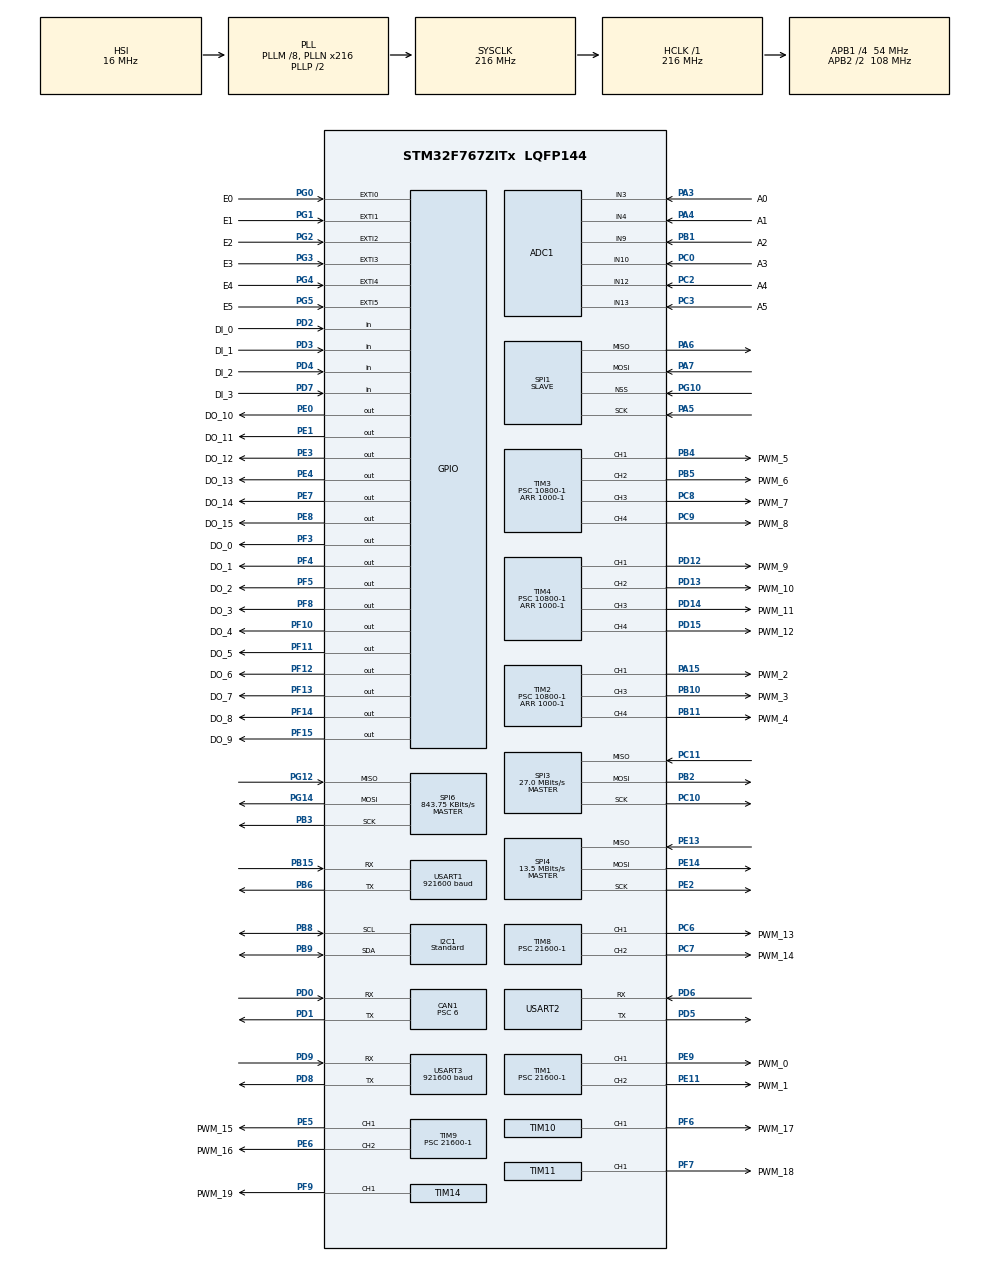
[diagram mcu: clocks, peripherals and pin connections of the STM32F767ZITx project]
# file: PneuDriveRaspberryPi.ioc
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ADC1.Channel-0\#ChannelRegularConversion=ADC_CHANNEL_3
ADC1.Channel-1\#ChannelRegularConversion=ADC_CHANNEL_4
ADC1.Channel-2\#ChannelRegularConversion=ADC_CHANNEL_9
ADC1.Channel-3\#ChannelRegularConversion=ADC_CHANNEL_10
ADC1.Channel-4\#ChannelRegularConversion=ADC_CHANNEL_12
ADC1.Channel-5\#ChannelRegularConversion=ADC_CHANNEL_13
ADC1.ContinuousConvMode=ENABLE
ADC1.DMAContinuousRequests=ENABLE
ADC1.EOCSelection=ADC_EOC_SEQ_CONV
ADC1.NbrOfConversion=6
ADC1.NbrOfConversionFlag=1
ADC1.Rank-0\#ChannelRegularConversion=1
ADC1.Rank-1\#ChannelRegularConversion=2
ADC1.Rank-2\#ChannelRegularConversion=3
ADC1.Rank-3\#ChannelRegularConversion=4
ADC1.Rank-4\#ChannelRegularConversion=5
ADC1.Rank-5\#ChannelRegularConversion=6
ADC1.SamplingTime-0\#ChannelRegularConversion=ADC_SAMPLETIME_480CYCLES
ADC1.SamplingTime-1\#ChannelRegularConversion=ADC_SAMPLETIME_480CYCLES
ADC1.SamplingTime-2\#ChannelRegularConversion=ADC_SAMPLETIME_480CYCLES
ADC1.SamplingTime-3\#ChannelRegularConversion=ADC_SAMPLETIME_480CYCLES
ADC1.SamplingTime-4\#ChannelRegularConversion=ADC_SAMPLETIME_480CYCLES
ADC1.SamplingTime-5\#ChannelRegularConversion=ADC_SAMPLETIME_480CYCLES
ADC1.ScanConvMode=ADC_SCAN_ENABLE
ADC1.master=1
CAN1.BS1=CAN_BS1_7TQ
CAN1.CalculateTimeQuantum=111.11111111111111
CAN1.NART=ENABLE
CAN1.Prescaler=6
CORTEX_M7.CPU_DCache=Enabled
CORTEX_M7.CPU_ICache=Enabled
Dma.ADC1.8.Direction=DMA_PERIPH_TO_MEMORY
Dma.ADC1.8.FIFOMode=DMA_FIFOMODE_DISABLE
Dma.ADC1.8.Instance=DMA2_Stream4
Dma.ADC1.8.MemDataAlignment=DMA_MDATAALIGN_HALFWORD
Dma.ADC1.8.MemInc=DMA_MINC_ENABLE
Dma.ADC1.8.Mode=DMA_CIRCULAR
Dma.ADC1.8.PeriphDataAlignment=DMA_PDATAALIGN_HALFWORD
Dma.ADC1.8.PeriphInc=DMA_PINC_DISABLE
Dma.ADC1.8.Priority=DMA_PRIORITY_LOW
Dma.Request0=SPI1_RX
Dma.Request1=SPI1_TX
Dma.Request10=USART1_TX
Dma.Request2=SPI3_RX
Dma.Request3=SPI3_TX
Dma.Request4=SPI4_RX
Dma.Request5=SPI4_TX
Dma.Request6=USART3_RX
Dma.Request7=USART3_TX
Dma.Request8=ADC1
Dma.Request9=USART1_RX
Dma.SPI1_RX.0.Direction=DMA_PERIPH_TO_MEMORY
Dma.SPI1_RX.0.FIFOMode=DMA_FIFOMODE_DISABLE
Dma.SPI1_RX.0.Instance=DMA2_Stream2
Dma.SPI1_RX.0.MemDataAlignment=DMA_MDATAALIGN_BYTE
Dma.SPI1_RX.0.MemInc=DMA_MINC_ENABLE
Dma.SPI1_RX.0.Mode=DMA_NORMAL
Dma.SPI1_RX.0.PeriphDataAlignment=DMA_PDATAALIGN_BYTE
Dma.SPI1_RX.0.PeriphInc=DMA_PINC_DISABLE
Dma.SPI1_RX.0.Priority=DMA_PRIORITY_VERY_HIGH
Dma.SPI1_TX.1.Direction=DMA_MEMORY_TO_PERIPH
Dma.SPI1_TX.1.FIFOMode=DMA_FIFOMODE_DISABLE
Dma.SPI1_TX.1.Instance=DMA2_Stream3
Dma.SPI1_TX.1.MemDataAlignment=DMA_MDATAALIGN_BYTE
Dma.SPI1_TX.1.MemInc=DMA_MINC_ENABLE
Dma.SPI1_TX.1.Mode=DMA_NORMAL
Dma.SPI1_TX.1.PeriphDataAlignment=DMA_PDATAALIGN_BYTE
Dma.SPI1_TX.1.PeriphInc=DMA_PINC_DISABLE
Dma.SPI1_TX.1.Priority=DMA_PRIORITY_VERY_HIGH
Dma.SPI3_RX.2.Direction=DMA_PERIPH_TO_MEMORY
Dma.SPI3_RX.2.FIFOMode=DMA_FIFOMODE_DISABLE
Dma.SPI3_RX.2.Instance=DMA1_Stream0
Dma.SPI3_RX.2.MemDataAlignment=DMA_MDATAALIGN_HALFWORD
Dma.SPI3_RX.2.MemInc=DMA_MINC_ENABLE
Dma.SPI3_RX.2.Mode=DMA_NORMAL
Dma.SPI3_RX.2.PeriphDataAlignment=DMA_PDATAALIGN_HALFWORD
Dma.SPI3_RX.2.PeriphInc=DMA_PINC_DISABLE
Dma.SPI3_RX.2.Priority=DMA_PRIORITY_HIGH
Dma.SPI3_TX.3.Direction=DMA_MEMORY_TO_PERIPH
Dma.SPI3_TX.3.FIFOMode=DMA_FIFOMODE_DISABLE
Dma.SPI3_TX.3.Instance=DMA1_Stream5
Dma.SPI3_TX.3.MemDataAlignment=DMA_MDATAALIGN_HALFWORD
Dma.SPI3_TX.3.MemInc=DMA_MINC_ENABLE
Dma.SPI3_TX.3.Mode=DMA_NORMAL
Dma.SPI3_TX.3.PeriphDataAlignment=DMA_PDATAALIGN_HALFWORD
Dma.SPI3_TX.3.PeriphInc=DMA_PINC_DISABLE
Dma.SPI3_TX.3.Priority=DMA_PRIORITY_HIGH
Dma.SPI4_RX.4.Direction=DMA_PERIPH_TO_MEMORY
Dma.SPI4_RX.4.FIFOMode=DMA_FIFOMODE_DISABLE
Dma.SPI4_RX.4.Instance=DMA2_Stream0
Dma.SPI4_RX.4.MemDataAlignment=DMA_MDATAALIGN_HALFWORD
Dma.SPI4_RX.4.MemInc=DMA_MINC_ENABLE
Dma.SPI4_RX.4.Mode=DMA_NORMAL
Dma.SPI4_RX.4.PeriphDataAlignment=DMA_PDATAALIGN_HALFWORD
Dma.SPI4_RX.4.PeriphInc=DMA_PINC_DISABLE
Dma.SPI4_RX.4.Priority=DMA_PRIORITY_MEDIUM
Dma.SPI4_TX.5.Direction=DMA_MEMORY_TO_PERIPH
Dma.SPI4_TX.5.FIFOMode=DMA_FIFOMODE_DISABLE
Dma.SPI4_TX.5.Instance=DMA2_Stream1
Dma.SPI4_TX.5.MemDataAlignment=DMA_MDATAALIGN_HALFWORD
Dma.SPI4_TX.5.MemInc=DMA_MINC_ENABLE
Dma.SPI4_TX.5.Mode=DMA_NORMAL
Dma.SPI4_TX.5.PeriphDataAlignment=DMA_PDATAALIGN_HALFWORD
Dma.SPI4_TX.5.PeriphInc=DMA_PINC_DISABLE
Dma.SPI4_TX.5.Priority=DMA_PRIORITY_MEDIUM
Dma.USART1_RX.9.Direction=DMA_PERIPH_TO_MEMORY
Dma.USART1_RX.9.FIFOMode=DMA_FIFOMODE_DISABLE
Dma.USART1_RX.9.Instance=DMA2_Stream5
Dma.USART1_RX.9.MemDataAlignment=DMA_MDATAALIGN_BYTE
Dma.USART1_RX.9.MemInc=DMA_MINC_ENABLE
Dma.USART1_RX.9.Mode=DMA_CIRCULAR
Dma.USART1_RX.9.PeriphDataAlignment=DMA_PDATAALIGN_BYTE
Dma.USART1_RX.9.PeriphInc=DMA_PINC_DISABLE
Dma.USART1_RX.9.Priority=DMA_PRIORITY_LOW
Dma.USART1_TX.10.Direction=DMA_MEMORY_TO_PERIPH
Dma.USART1_TX.10.FIFOMode=DMA_FIFOMODE_DISABLE
Dma.USART1_TX.10.Instance=DMA2_Stream7
Dma.USART1_TX.10.MemDataAlignment=DMA_MDATAALIGN_BYTE
Dma.USART1_TX.10.MemInc=DMA_MINC_ENABLE
Dma.USART1_TX.10.Mode=DMA_NORMAL
Dma.USART1_TX.10.PeriphDataAlignment=DMA_PDATAALIGN_BYTE
Dma.USART1_TX.10.PeriphInc=DMA_PINC_DISABLE
Dma.USART1_TX.10.Priority=DMA_PRIORITY_LOW
Dma.USART3_RX.6.Direction=DMA_PERIPH_TO_MEMORY
Dma.USART3_RX.6.FIFOMode=DMA_FIFOMODE_DISABLE
Dma.USART3_RX.6.Instance=DMA1_Stream1
Dma.USART3_RX.6.MemDataAlignment=DMA_MDATAALIGN_BYTE
Dma.USART3_RX.6.MemInc=DMA_MINC_ENABLE
Dma.USART3_RX.6.Mode=DMA_NORMAL
Dma.USART3_RX.6.PeriphDataAlignment=DMA_PDATAALIGN_BYTE
Dma.USART3_RX.6.PeriphInc=DMA_PINC_DISABLE
Dma.USART3_RX.6.Priority=DMA_PRIORITY_HIGH
Dma.USART3_TX.7.Direction=DMA_MEMORY_TO_PERIPH
Dma.USART3_TX.7.FIFOMode=DMA_FIFOMODE_DISABLE
Dma.USART3_TX.7.Instance=DMA1_Stream4
Dma.USART3_TX.7.MemDataAlignment=DMA_MDATAALIGN_BYTE
Dma.USART3_TX.7.MemInc=DMA_MINC_ENABLE
Dma.USART3_TX.7.Mode=DMA_NORMAL
Dma.USART3_TX.7.PeriphDataAlignment=DMA_PDATAALIGN_BYTE
Dma.USART3_TX.7.PeriphInc=DMA_PINC_DISABLE
Dma.USART3_TX.7.Priority=DMA_PRIORITY_MEDIUM
FREERTOS.INCLUDE_vTaskDelayUntil=1
FREERTOS.MEMORY_ALLOCATION=1
FREERTOS.Tasks01=sendTask,-1,4096,sendTaskFunc,Default,NULL,Static,sendTaskBuffer,sendTaskControlBlock;controlTask,1,4096,controlTaskFunc,Default,NULL,Static,controlTaskBuffer,controlTaskControlBlock
FREERTOS.configUSE_TRACE_FACILITY=0
I2C1.I2C_Speed_Mode=I2C_Standard
I2C1.Timing=0x20404768
Mcu.Family=STM32F7
Mcu.Name=STM32F767ZITx
Mcu.Package=LQFP144
NVIC.CAN1_RX0_IRQn=true\:5\:0\:false\:false\:true\:true\:true\:true
NVIC.CAN1_RX1_IRQn=true\:5\:0\:false\:false\:true\:true\:true\:true
NVIC.DMA1_Stream0_IRQn=true\:5\:0\:false\:false\:true\:true\:false\:true
NVIC.DMA1_Stream1_IRQn=true\:5\:0\:false\:false\:true\:true\:false\:true
NVIC.DMA1_Stream4_IRQn=true\:5\:0\:false\:false\:true\:true\:false\:true
NVIC.DMA1_Stream5_IRQn=true\:5\:0\:false\:false\:true\:true\:false\:true
NVIC.DMA2_Stream0_IRQn=true\:5\:0\:false\:false\:true\:true\:false\:true
NVIC.DMA2_Stream1_IRQn=true\:5\:0\:false\:false\:true\:true\:false\:true
NVIC.DMA2_Stream2_IRQn=true\:5\:0\:false\:false\:true\:true\:false\:true
NVIC.DMA2_Stream3_IRQn=true\:5\:0\:false\:false\:true\:true\:false\:true
NVIC.DMA2_Stream4_IRQn=true\:5\:0\:false\:false\:true\:true\:false\:true
NVIC.DMA2_Stream5_IRQn=true\:5\:0\:false\:false\:true\:true\:false\:true
NVIC.DMA2_Stream7_IRQn=true\:5\:0\:false\:false\:true\:true\:false\:true
NVIC.EXTI0_IRQn=true\:5\:0\:false\:false\:true\:true\:true\:true
NVIC.EXTI1_IRQn=true\:5\:0\:false\:false\:true\:true\:true\:true
NVIC.EXTI2_IRQn=true\:5\:0\:false\:false\:true\:true\:true\:true
NVIC.EXTI3_IRQn=true\:5\:0\:false\:false\:true\:true\:true\:true
NVIC.EXTI4_IRQn=true\:5\:0\:false\:false\:true\:true\:true\:true
NVIC.EXTI9_5_IRQn=true\:5\:0\:false\:false\:true\:true\:true\:true
NVIC.I2C1_EV_IRQn=true\:0\:0\:false\:false\:true\:false\:true\:true
NVIC.PriorityGroup=NVIC_PRIORITYGROUP_4
NVIC.SPI6_IRQn=true\:5\:0\:false\:false\:true\:true\:true\:true
NVIC.TIM1_UP_TIM10_IRQn=true\:5\:0\:false\:false\:true\:true\:true\:true
NVIC.TIM5_IRQn=true\:0\:0\:false\:false\:true\:false\:false\:true
NVIC.TimeBase=TIM5_IRQn
NVIC.TimeBaseIP=TIM5
NVIC.USART1_IRQn=true\:5\:0\:false\:false\:true\:true\:true\:true
NVIC.USART2_IRQn=true\:5\:0\:false\:false\:true\:true\:true\:true
NVIC.USART3_IRQn=true\:5\:0\:false\:false\:true\:true\:true\:true
PA13.Signal=SYS_JTMS-SWDIO
PA14.Signal=SYS_JTCK-SWCLK
PA15.GPIO_Label=PWM_2
PA15.Signal=S_TIM2_CH1_ETR
PA3.GPIO_Label=A0
PA3.Signal=ADCx_IN3
PA4.GPIO_Label=A1
PA4.Signal=ADCx_IN4
PA5.Mode=Full_Duplex_Slave
PA5.Signal=SPI1_SCK
PA6.Mode=Full_Duplex_Slave
PA6.Signal=SPI1_MISO
PA7.GPIO_PuPd=GPIO_PULLUP
PA7.Mode=Full_Duplex_Slave
PA7.Signal=SPI1_MOSI
PB1.GPIO_Label=A2
PB1.Signal=ADCx_IN9
PB10.GPIO_Label=PWM_3
PB10.Signal=S_TIM2_CH3
PB11.GPIO_Label=PWM_4
PB11.Signal=S_TIM2_CH4
PB15.GPIO_PuPd=GPIO_PULLDOWN
PB15.Mode=Asynchronous
PB15.Signal=USART1_RX
PB2.Mode=Full_Duplex_Master
PB2.Signal=SPI3_MOSI
PB3.Mode=Full_Duplex_Master
PB3.Signal=SPI6_SCK
PB4.GPIO_Label=PWM_5
PB4.Signal=S_TIM3_CH1
PB5.GPIO_Label=PWM_6
PB5.Signal=S_TIM3_CH2
PB6.GPIO_PuPd=GPIO_PULLDOWN
PB6.Mode=Asynchronous
PB6.Signal=USART1_TX
PB8.Mode=I2C
PB8.Signal=I2C1_SCL
PB9.Mode=I2C
PB9.Signal=I2C1_SDA
PC0.GPIO_Label=A3
PC0.Signal=ADCx_IN10
PC10.Mode=Full_Duplex_Master
PC10.Signal=SPI3_SCK
PC11.Mode=Full_Duplex_Master
PC11.Signal=SPI3_MISO
PC2.GPIO_Label=A4
PC2.Signal=ADCx_IN12
PC3.GPIO_Label=A5
PC3.Signal=ADCx_IN13
PC6.GPIO_Label=PWM_13
PC6.Signal=S_TIM8_CH1
PC7.GPIO_Label=PWM_14
PC7.Signal=S_TIM8_CH2
PC8.GPIO_Label=PWM_7
PC8.Signal=S_TIM3_CH3
PC9.GPIO_Label=PWM_8
PC9.Signal=S_TIM3_CH4
PD0.Mode=Master
PD0.Signal=CAN1_RX
PD1.Mode=Master
PD1.Signal=CAN1_TX
PD12.GPIO_Label=PWM_9
PD12.Signal=S_TIM4_CH1
PD13.GPIO_Label=PWM_10
PD13.Signal=S_TIM4_CH2
PD14.GPIO_Label=PWM_11
PD14.Signal=S_TIM4_CH3
PD15.GPIO_Label=PWM_12
PD15.Signal=S_TIM4_CH4
PD2.GPIO_Label=DI_0
PD2.Signal=GPIO_Input
PD3.GPIO_Label=DI_1
PD3.Signal=GPIO_Input
PD4.GPIO_Label=DI_2
PD4.Signal=GPIO_Input
PD5.GPIO_PuPd=GPIO_PULLDOWN
PD5.Mode=Asynchronous
PD5.Signal=USART2_TX
PD6.GPIO_PuPd=GPIO_PULLDOWN
PD6.Mode=Asynchronous
PD6.Signal=USART2_RX
PD7.GPIO_Label=DI_3
PD7.Signal=GPIO_Input
PD8.GPIO_PuPd=GPIO_PULLDOWN
PD8.Mode=Asynchronous
PD8.Signal=USART3_TX
PD9.GPIO_PuPd=GPIO_PULLDOWN
PD9.Mode=Asynchronous
PD9.Signal=USART3_RX
PE0.GPIO_Label=DO_10
PE0.GPIO_PuPd=GPIO_PULLDOWN
PE0.Signal=GPIO_Output
PE1.GPIO_Label=DO_11
PE1.GPIO_PuPd=GPIO_PULLDOWN
PE1.Signal=GPIO_Output
PE11.GPIO_Label=PWM_1
PE11.Signal=S_TIM1_CH2
PE13.Mode=Full_Duplex_Master
PE13.Signal=SPI4_MISO
PE14.Mode=Full_Duplex_Master
PE14.Signal=SPI4_MOSI
PE2.Mode=Full_Duplex_Master
PE2.Signal=SPI4_SCK
PE3.GPIO_Label=DO_12
PE3.GPIO_PuPd=GPIO_PULLDOWN
PE3.Signal=GPIO_Output
PE4.GPIO_Label=DO_13
PE4.GPIO_PuPd=GPIO_PULLDOWN
PE4.Signal=GPIO_Output
PE5.GPIO_Label=PWM_15
PE5.Signal=S_TIM9_CH1
PE6.GPIO_Label=PWM_16
PE6.Signal=S_TIM9_CH2
PE7.GPIO_Label=DO_14
PE7.GPIO_PuPd=GPIO_PULLDOWN
PE7.Signal=GPIO_Output
PE8.GPIO_Label=DO_15
PE8.GPIO_PuPd=GPIO_PULLDOWN
PE8.Signal=GPIO_Output
PE9.GPIO_Label=PWM_0
PE9.Signal=S_TIM1_CH1
PF10.GPIO_Label=DO_4
PF10.GPIO_PuPd=GPIO_PULLDOWN
PF10.Signal=GPIO_Output
PF11.GPIO_Label=DO_5
PF11.GPIO_PuPd=GPIO_PULLDOWN
PF11.Signal=GPIO_Output
PF12.GPIO_Label=DO_6
PF12.GPIO_PuPd=GPIO_PULLDOWN
PF12.Signal=GPIO_Output
PF13.GPIO_Label=DO_7
PF13.GPIO_PuPd=GPIO_PULLDOWN
PF13.Signal=GPIO_Output
PF14.GPIO_Label=DO_8
PF14.GPIO_PuPd=GPIO_PULLDOWN
PF14.Signal=GPIO_Output
PF15.GPIO_Label=DO_9
PF15.GPIO_PuPd=GPIO_PULLDOWN
PF15.Signal=GPIO_Output
PF3.GPIO_Label=DO_0
PF3.GPIO_PuPd=GPIO_PULLDOWN
PF3.Signal=GPIO_Output
PF4.GPIO_Label=DO_1
PF4.GPIO_PuPd=GPIO_PULLDOWN
PF4.Signal=GPIO_Output
PF5.GPIO_Label=DO_2
PF5.GPIO_PuPd=GPIO_PULLDOWN
PF5.Signal=GPIO_Output
PF6.GPIO_Label=PWM_17
PF6.Signal=S_TIM10_CH1
PF7.GPIO_Label=PWM_18
PF7.Signal=S_TIM11_CH1
PF8.GPIO_Label=DO_3
PF8.GPIO_PuPd=GPIO_PULLDOWN
PF8.Signal=GPIO_Output
PF9.GPIO_Label=PWM_19
PF9.Signal=S_TIM14_CH1
PG0.GPIO_Label=E0
PG0.GPIO_ModeDefaultEXTI=GPIO_MODE_IT_FALLING
PG0.GPIO_PuPd=GPIO_PULLDOWN
PG0.Signal=GPXTI0
PG1.GPIO_Label=E1
PG1.GPIO_ModeDefaultEXTI=GPIO_MODE_IT_FALLING
PG1.GPIO_PuPd=GPIO_PULLDOWN
PG1.Signal=GPXTI1
PG10.Mode=NSS_Signal_Hard_Input
PG10.Signal=SPI1_NSS
PG12.Mode=Full_Duplex_Master
PG12.Signal=SPI6_MISO
PG14.Mode=Full_Duplex_Master
PG14.Signal=SPI6_MOSI
PG2.GPIO_Label=E2
PG2.GPIO_ModeDefaultEXTI=GPIO_MODE_IT_FALLING
PG2.GPIO_PuPd=GPIO_PULLDOWN
PG2.Signal=GPXTI2
PG3.GPIO_Label=E3
PG3.GPIO_ModeDefaultEXTI=GPIO_MODE_IT_FALLING
PG3.GPIO_PuPd=GPIO_PULLDOWN
PG3.Signal=GPXTI3
PG4.GPIO_Label=E4
PG4.GPIO_ModeDefaultEXTI=GPIO_MODE_IT_FALLING
PG4.GPIO_PuPd=GPIO_PULLDOWN
PG4.Signal=GPXTI4
PG5.GPIO_Label=E5
PG5.GPIO_ModeDefaultEXTI=GPIO_MODE_IT_FALLING
PG5.GPIO_PuPd=GPIO_PULLDOWN
PG5.Signal=GPXTI5
ProjectManager.HeapSize=0x200
ProjectManager.StackSize=0x400
ProjectManager.TargetToolchain=STM32CubeIDE
RCC.AHBFreq_Value=216000000
RCC.APB1CLKDivider=RCC_HCLK_DIV4
RCC.APB1Freq_Value=54000000
RCC.APB1TimFreq_Value=108000000
RCC.APB2CLKDivider=RCC_HCLK_DIV2
RCC.APB2Freq_Value=108000000
RCC.APB2TimFreq_Value=216000000
RCC.CortexFreq_Value=216000000
RCC.HCLKFreq_Value=216000000
RCC.HSE_VALUE=25000000
RCC.HSI_VALUE=16000000
RCC.LSE_VALUE=32768
RCC.PLLM=8
RCC.PLLN=216
RCC.SYSCLKFreq_VALUE=216000000
RCC.SYSCLKSource=RCC_SYSCLKSOURCE_PLLCLK
RCC.USBFreq_Value=216000000
RCC.VCOOutputFreq_Value=432000000
SH.ADCx_IN10.0=ADC1_IN10,IN10
SH.ADCx_IN12.0=ADC1_IN12,IN12
SH.ADCx_IN13.0=ADC1_IN13,IN13
SH.ADCx_IN3.0=ADC1_IN3,IN3
SH.ADCx_IN4.0=ADC1_IN4,IN4
SH.ADCx_IN9.0=ADC1_IN9,IN9
SH.S_TIM10_CH1.0=TIM10_CH1,PWM Generation1 CH1
SH.S_TIM11_CH1.0=TIM11_CH1,PWM Generation1 CH1
SH.S_TIM14_CH1.0=TIM14_CH1,PWM Generation1 CH1
SH.S_TIM1_CH1.0=TIM1_CH1,PWM Generation1 CH1
SH.S_TIM1_CH2.0=TIM1_CH2,PWM Generation2 CH2
SH.S_TIM2_CH1_ETR.0=TIM2_CH1,PWM Generation1 CH1
SH.S_TIM2_CH3.0=TIM2_CH3,PWM Generation3 CH3
SH.S_TIM2_CH4.0=TIM2_CH4,PWM Generation4 CH4
SH.S_TIM3_CH1.0=TIM3_CH1,PWM Generation1 CH1
SH.S_TIM3_CH2.0=TIM3_CH2,PWM Generation2 CH2
SH.S_TIM3_CH3.0=TIM3_CH3,PWM Generation3 CH3
SH.S_TIM3_CH4.0=TIM3_CH4,PWM Generation4 CH4
SH.S_TIM4_CH1.0=TIM4_CH1,PWM Generation1 CH1
SH.S_TIM4_CH2.0=TIM4_CH2,PWM Generation2 CH2
SH.S_TIM4_CH3.0=TIM4_CH3,PWM Generation3 CH3
SH.S_TIM4_CH4.0=TIM4_CH4,PWM Generation4 CH4
SH.S_TIM8_CH1.0=TIM8_CH1,PWM Generation1 CH1
SH.S_TIM8_CH2.0=TIM8_CH2,PWM Generation2 CH2
SH.S_TIM9_CH1.0=TIM9_CH1,PWM Generation1 CH1
SH.S_TIM9_CH2.0=TIM9_CH2,PWM Generation2 CH2
SPI1.CLKPhase=SPI_PHASE_2EDGE
SPI1.CLKPolarity=SPI_POLARITY_LOW
SPI1.DataSize=SPI_DATASIZE_8BIT
SPI1.Direction=SPI_DIRECTION_2LINES
SPI1.Mode=SPI_MODE_SLAVE
SPI1.VirtualNSS=VM_NSSHARD
SPI1.VirtualType=VM_SLAVE
SPI3.BaudRatePrescaler=SPI_BAUDRATEPRESCALER_2
SPI3.CLKPhase=SPI_PHASE_1EDGE
SPI3.CLKPolarity=SPI_POLARITY_LOW
SPI3.CalculateBaudRate=27.0 MBits/s
SPI3.DataSize=SPI_DATASIZE_8BIT
SPI3.Direction=SPI_DIRECTION_2LINES
SPI3.Mode=SPI_MODE_MASTER
SPI3.VirtualType=VM_MASTER
SPI4.BaudRatePrescaler=SPI_BAUDRATEPRESCALER_8
SPI4.CLKPolarity=SPI_POLARITY_HIGH
SPI4.CalculateBaudRate=13.5 MBits/s
SPI4.DataSize=SPI_DATASIZE_16BIT
SPI4.Direction=SPI_DIRECTION_2LINES
SPI4.Mode=SPI_MODE_MASTER
SPI4.VirtualType=VM_MASTER
SPI6.BaudRatePrescaler=SPI_BAUDRATEPRESCALER_128
SPI6.CalculateBaudRate=843.75 KBits/s
SPI6.DataSize=SPI_DATASIZE_16BIT
SPI6.Direction=SPI_DIRECTION_2LINES
SPI6.Mode=SPI_MODE_MASTER
SPI6.VirtualType=VM_MASTER
TIM1.Channel-PWM\ Generation1\ CH1=TIM_CHANNEL_1
TIM1.Channel-PWM\ Generation2\ CH2=TIM_CHANNEL_2
TIM1.Period=1000-1
TIM1.Prescaler=21600-1
TIM10.Channel=TIM_CHANNEL_1
TIM10.Period=1000-1
TIM10.Prescaler=21600-1
TIM11.Channel=TIM_CHANNEL_1
TIM11.Period=1000-1
TIM11.Prescaler=21600-1
TIM14.Channel=TIM_CHANNEL_1
TIM14.Period=1000-1
TIM14.Prescaler=10800-1
TIM2.Channel-PWM\ Generation1\ CH1=TIM_CHANNEL_1
TIM2.Channel-PWM\ Generation3\ CH3=TIM_CHANNEL_3
TIM2.Channel-PWM\ Generation4\ CH4=TIM_CHANNEL_4
TIM2.Period=1000-1
TIM2.Prescaler=10800-1
TIM3.Channel-PWM\ Generation1\ CH1=TIM_CHANNEL_1
TIM3.Channel-PWM\ Generation2\ CH2=TIM_CHANNEL_2
TIM3.Channel-PWM\ Generation3\ CH3=TIM_CHANNEL_3
TIM3.Channel-PWM\ Generation4\ CH4=TIM_CHANNEL_4
TIM3.Period=1000-1
TIM3.Prescaler=10800-1
TIM4.Channel-PWM\ Generation1\ CH1=TIM_CHANNEL_1
TIM4.Channel-PWM\ Generation2\ CH2=TIM_CHANNEL_2
TIM4.Channel-PWM\ Generation3\ CH3=TIM_CHANNEL_3
TIM4.Channel-PWM\ Generation4\ CH4=TIM_CHANNEL_4
TIM4.Period=1000-1
TIM4.Prescaler=10800-1
TIM7.Period=65535
TIM8.Channel-PWM\ Generation1\ CH1=TIM_CHANNEL_1
TIM8.Channel-PWM\ Generation2\ CH2=TIM_CHANNEL_2
TIM8.Period=1000-1
TIM8.Prescaler=21600-1
TIM9.Channel-PWM\ Generation1\ CH1=TIM_CHANNEL_1
TIM9.Channel-PWM\ Generation2\ CH2=TIM_CHANNEL_2
TIM9.Period=1000-1
TIM9.Prescaler=21600-1
USART1.BaudRate=921600
USART1.VirtualMode-Asynchronous=VM_ASYNC
USART2.VirtualMode-Asynchronous=VM_ASYNC
USART3.BaudRate=921600
USART3.VirtualMode-Asynchronous=VM_ASYNC
VP_FREERTOS_VS_CMSIS_V1.Mode=CMSIS_V1
VP_SYS_VS_tim5.Mode=TIM5
VP_TIM10_VS_ClockSourceINT.Mode=Enable_Timer
VP_TIM11_VS_ClockSourceINT.Mode=Enable_Timer
VP_TIM14_VS_ClockSourceINT.Mode=Enable_Timer
VP_TIM1_VS_ClockSourceINT.Mode=Internal
VP_TIM2_VS_ClockSourceINT.Mode=Internal
VP_TIM7_VS_ClockSourceINT.Mode=Enable_Timer
VP_TIM8_VS_ClockSourceINT.Mode=Internal
VP_TIM9_VS_ClockSourceINT.Mode=Internal
board=custom

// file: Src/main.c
/* USER CODE BEGIN Header */
/**
  ******************************************************************************
  * @file           : main.c
  * @brief          : Main program body
  ******************************************************************************
  * @attention
  *
  * <h2><center>&copy; Copyright (c) 2019 STMicroelectronics.
  * All rights reserved.</center></h2>
  *
  * This software component is licensed by ST under BSD 3-Clause license,
  * the "License"; You may not use this file except in compliance with the
  * License. You may obtain a copy of the License at:
  *                        opensource.org/licenses/BSD-3-Clause
  *
  ******************************************************************************
  */
/* USER CODE END Header */
#include "main.h"
#include "cmsis_os.h"
#include "adc.h"
#include "can.h"
#include "dma.h"
#include "i2c.h"
#include "spi.h"
#include "tim.h"
#include "usart.h"
#include "gpio.h"

/* USER CODE BEGIN Includes */
#include "PneuDriveLL.h"
#include "myUsartFunction.h"
#include "ADBoard.h"
#include "DABoard.h"
#include "PWMBoardI2C.h"
#include "PWMBoardSPI.h"
#include "builtInAnalog.h"
#include "builtInPWM.h"
#include "builtInDigital.h"
#include "spiSlave.h"
/* USER CODE END Includes */

void SystemClock_Config(void);
void MX_FREERTOS_Init(void);

int main(void)
{

  /* Enable I-Cache---------------------------------------------------------*/
  SCB_EnableICache();

  /* Enable D-Cache---------------------------------------------------------*/
  SCB_EnableDCache();

  /* MCU Configuration--------------------------------------------------------*/

  /* Reset of all peripherals, Initializes the Flash interface and the Systick. */
  HAL_Init();

  /* Configure the system clock */
  SystemClock_Config();

  /* Initialize all configured peripherals */
  MX_GPIO_Init();
  MX_DMA_Init();
  MX_ADC1_Init();
  MX_TIM1_Init();
  MX_TIM2_Init();
  MX_TIM3_Init();
  MX_TIM4_Init();
  MX_TIM7_Init();
  MX_TIM8_Init();
  MX_TIM9_Init();
  MX_TIM10_Init();
  MX_TIM11_Init();
  MX_TIM14_Init();
  MX_SPI1_Init();
  MX_SPI3_Init();
  MX_SPI4_Init();
  MX_SPI6_Init();
  MX_USART1_UART_Init();
  MX_USART3_UART_Init();
  MX_I2C1_Init();
  MX_USART2_UART_Init();
  MX_CAN1_Init();
  /* USER CODE BEGIN 2 */
	/*******************************Usart1 and Usart3**************************/
	my_UsartInit();

	/*******************************Analog init***************************/
	//AnaBuiltInStart();

#if (ADBOARD_NUM>0)
	ADBoard_Init();
#endif

	/******************************  PWM  init***************************/
	PWMBuiltIn_init();

#if (PWMBOARDSPI_NUM>0)
	PWMBoardSPI_init();
#endif

#if (PWMBOARDI2C_NUM>0)
	PWMBoardI2C_init();
#endif

	/******************************* setup() function**************************/
	setup();
  /* USER CODE END 2 */

  /* Call init function for freertos objects (in freertos.c) */
  MX_FREERTOS_Init();
  /* Start scheduler */
  osKernelStart();

  /* We should never get here as control is now taken by the scheduler */
  /* Infinite loop */
  while (1)
  {

  }
}

void SystemClock_Config(void)
{
  RCC_OscInitTypeDef RCC_OscInitStruct = {0};
  RCC_ClkInitTypeDef RCC_ClkInitStruct = {0};
  RCC_PeriphCLKInitTypeDef PeriphClkInitStruct = {0};

  /** Configure the main internal regulator output voltage
  */
  __HAL_RCC_PWR_CLK_ENABLE();
  __HAL_PWR_VOLTAGESCALING_CONFIG(PWR_REGULATOR_VOLTAGE_SCALE1);
  /** Initializes the RCC Oscillators according to the specified parameters
  * in the RCC_OscInitTypeDef structure.
  */
  RCC_OscInitStruct.OscillatorType = RCC_OSCILLATORTYPE_HSI;
  RCC_OscInitStruct.HSIState = RCC_HSI_ON;
  RCC_OscInitStruct.HSICalibrationValue = RCC_HSICALIBRATION_DEFAULT;
  RCC_OscInitStruct.PLL.PLLState = RCC_PLL_ON;
  RCC_OscInitStruct.PLL.PLLSource = RCC_PLLSOURCE_HSI;
  RCC_OscInitStruct.PLL.PLLM = 8;
  RCC_OscInitStruct.PLL.PLLN = 216;
  RCC_OscInitStruct.PLL.PLLP = RCC_PLLP_DIV2;
  RCC_OscInitStruct.PLL.PLLQ = 2;
  if (HAL_RCC_OscConfig(&RCC_OscInitStruct) != HAL_OK)
  {
    Error_Handler();
  }
  /** Activate the Over-Drive mode
  */
  if (HAL_PWREx_EnableOverDrive() != HAL_OK)
  {
    Error_Handler();
  }
  /** Initializes the CPU, AHB and APB buses clocks
  */
  RCC_ClkInitStruct.ClockType = RCC_CLOCKTYPE_HCLK|RCC_CLOCKTYPE_SYSCLK
                              |RCC_CLOCKTYPE_PCLK1|RCC_CLOCKTYPE_PCLK2;
  RCC_ClkInitStruct.SYSCLKSource = RCC_SYSCLKSOURCE_PLLCLK;
  RCC_ClkInitStruct.AHBCLKDivider = RCC_SYSCLK_DIV1;
  RCC_ClkInitStruct.APB1CLKDivider = RCC_HCLK_DIV4;
  RCC_ClkInitStruct.APB2CLKDivider = RCC_HCLK_DIV2;

  if (HAL_RCC_ClockConfig(&RCC_ClkInitStruct, FLASH_LATENCY_7) != HAL_OK)
  {
    Error_Handler();
  }
  PeriphClkInitStruct.PeriphClockSelection = RCC_PERIPHCLK_USART1|RCC_PERIPHCLK_USART2
                              |RCC_PERIPHCLK_USART3|RCC_PERIPHCLK_I2C1;
  PeriphClkInitStruct.Usart1ClockSelection = RCC_USART1CLKSOURCE_PCLK2;
  PeriphClkInitStruct.Usart2ClockSelection = RCC_USART2CLKSOURCE_PCLK1;
  PeriphClkInitStruct.Usart3ClockSelection = RCC_USART3CLKSOURCE_PCLK1;
  PeriphClkInitStruct.I2c1ClockSelection = RCC_I2C1CLKSOURCE_PCLK1;
  if (HAL_RCCEx_PeriphCLKConfig(&PeriphClkInitStruct) != HAL_OK)
  {
    Error_Handler();
  }
}

/* USER CODE BEGIN 4 */
/*-----------------------Call back functions----------------------*/
void HAL_SPI_TxRxCpltCallback(SPI_HandleTypeDef *hspi)
{

#if (ADBOARD_NUM>0)
	ADBoard_SPICallback(hspi);
#endif
	slaveSPITxRxCpltCallback(hspi);

}
void HAL_SPI_ErrorCallback(SPI_HandleTypeDef *hspi)
{
	slaveSPIErrorCallback(hspi);

}
void HAL_GPIO_EXTI_Callback(uint16_t GPIO_Pin)
{
	int ret = 1;
	static int INTChannel=0;
	if(GPIO_Pin==E0_Pin){
		INTChannel=0;
	}
	else if(GPIO_Pin==E1_Pin){
		INTChannel=1;
	}else if(GPIO_Pin==E2_Pin){
		INTChannel=2;
	}else if(GPIO_Pin==E3_Pin){
		INTChannel=3;
	}else if(GPIO_Pin==E4_Pin){
		INTChannel=4;
	}
	else if(GPIO_Pin==E5_Pin){
		INTChannel=5;
	}
#if (ADBOARD_NUM>0)
	ret = ADBoard_BUSYCallback(INTChannel);
#endif
	if (ret)
		interruptCallback(INTChannel);
}

void HAL_I2C_ErrorCallback(I2C_HandleTypeDef *hi2c){
	uint32_t SDA_PIN = GPIO_PIN_0;
	uint32_t SCL_PIN = GPIO_PIN_1;
	GPIO_TypeDef *SDA_PORT=GPIOF;
	GPIO_TypeDef *SCL_PORT=GPIOF;
	GPIO_InitTypeDef GPIO_InitStructure;
	hi2c->Instance->CR1 &= ~I2C_CR1_PE;
	GPIO_InitStructure.Mode         = GPIO_MODE_OUTPUT_OD;
	GPIO_InitStructure.Pull         = GPIO_PULLUP;
	GPIO_InitStructure.Speed        = GPIO_SPEED_FREQ_HIGH;
	GPIO_InitStructure.Pin          = SCL_PIN;
	HAL_GPIO_Init(SCL_PORT, &GPIO_InitStructure);
	HAL_GPIO_WritePin(SCL_PORT, SCL_PIN, GPIO_PIN_SET);
	GPIO_InitStructure.Pin          = SDA_PIN;
	HAL_GPIO_Init(SDA_PORT, &GPIO_InitStructure);
	HAL_GPIO_WritePin(SDA_PORT, SDA_PIN, GPIO_PIN_SET);
	HAL_GPIO_WritePin(SDA_PORT, SDA_PIN, GPIO_PIN_RESET);
	HAL_GPIO_WritePin(SCL_PORT, SCL_PIN, GPIO_PIN_RESET);
	HAL_GPIO_WritePin(SCL_PORT, SCL_PIN, GPIO_PIN_SET);
	HAL_GPIO_WritePin(SDA_PORT, SDA_PIN, GPIO_PIN_SET);

	GPIO_InitStructure.Mode = GPIO_MODE_AF_OD;
	GPIO_InitStructure.Pull = GPIO_PULLUP;
	GPIO_InitStructure.Speed = GPIO_SPEED_FREQ_VERY_HIGH;
	GPIO_InitStructure.Alternate = GPIO_AF4_I2C2;
	GPIO_InitStructure.Pin          = SCL_PIN;
	HAL_GPIO_Init(SCL_PORT, &GPIO_InitStructure);
	GPIO_InitStructure.Pin          = SDA_PIN;
	HAL_GPIO_Init(SDA_PORT, &GPIO_InitStructure);
//	hi2c->Instance->CR1 |= I2C_CR1_SWRST;
//	asm("nop");
//	hi2c->Instance->CR1 &= ~I2C_CR1_SWRST;
//	asm("nop");
	hi2c->Instance->CR1 |= I2C_CR1_PE;
	HAL_I2C_Init(hi2c);
}
/* USER CODE END 4 */

void HAL_TIM_PeriodElapsedCallback(TIM_HandleTypeDef *htim)
{
  if (htim->Instance == TIM5) {
    HAL_IncTick();
  }
}

void Error_Handler(void)
{
}

/************************ (C) COPYRIGHT STMicroelectronics *****END OF FILE****/

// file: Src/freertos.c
/* USER CODE BEGIN Header */
/**
  ******************************************************************************
  * File Name          : freertos.c
  * Description        : Code for freertos applications
  ******************************************************************************
  * @attention
  *
  * <h2><center>&copy; Copyright (c) 2019 STMicroelectronics.
  * All rights reserved.</center></h2>
  *
  * This software component is licensed by ST under Ultimate Liberty license
  * SLA0044, the "License"; You may not use this file except in compliance with
  * the License. You may obtain a copy of the License at:
  *                             www.st.com/SLA0044
  *
  ******************************************************************************
  */
/* USER CODE END Header */

#include "FreeRTOS.h"
#include "task.h"
#include "main.h"
#include "cmsis_os.h"

/* USER CODE BEGIN Includes */
#include "PneuDriveLL.h"

#include "builtInAnalog.h"
#include "PWMBoardSPI.h"
#include "ADBoard.h"
/* USER CODE END Includes */

osThreadId sendTaskHandle;
uint32_t sendTaskBuffer[ 4096 ];
osStaticThreadDef_t sendTaskControlBlock;
osThreadId controlTaskHandle;
uint32_t controlTaskBuffer[ 4096 ];
osStaticThreadDef_t controlTaskControlBlock;

void sendTaskFunc(void const * argument);
void controlTaskFunc(void const * argument);

void MX_FREERTOS_Init(void); /* (MISRA C 2004 rule 8.1) */

/* GetIdleTaskMemory prototype (linked to static allocation support) */
void vApplicationGetIdleTaskMemory( StaticTask_t **ppxIdleTaskTCBBuffer, StackType_t **ppxIdleTaskStackBuffer, uint32_t *pulIdleTaskStackSize );

/* USER CODE BEGIN GET_IDLE_TASK_MEMORY */
static StaticTask_t xIdleTaskTCBBuffer;
static StackType_t xIdleStack[configMINIMAL_STACK_SIZE];

void vApplicationGetIdleTaskMemory( StaticTask_t **ppxIdleTaskTCBBuffer, StackType_t **ppxIdleTaskStackBuffer, uint32_t *pulIdleTaskStackSize )
{
  *ppxIdleTaskTCBBuffer = &xIdleTaskTCBBuffer;
  *ppxIdleTaskStackBuffer = &xIdleStack[0];
  *pulIdleTaskStackSize = configMINIMAL_STACK_SIZE;
  /* place for user code */
}
/* USER CODE END GET_IDLE_TASK_MEMORY */

void MX_FREERTOS_Init(void) {

  /* Create the thread(s) */
  /* definition and creation of sendTask */
  osThreadStaticDef(sendTask, sendTaskFunc, osPriorityBelowNormal, 0, 4096, sendTaskBuffer, &sendTaskControlBlock);
  sendTaskHandle = osThreadCreate(osThread(sendTask), NULL);

  /* definition and creation of controlTask */
  osThreadStaticDef(controlTask, controlTaskFunc, osPriorityAboveNormal, 0, 4096, controlTaskBuffer, &controlTaskControlBlock);
  controlTaskHandle = osThreadCreate(osThread(controlTask), NULL);

}

void sendTaskFunc(void const * argument)
{
  /* USER CODE BEGIN sendTaskFunc */
	TickType_t xLastWakeTime=xTaskGetTickCount();
	TickType_t sendTaskPeriod=pdMS_TO_TICKS(1);
	static int32_t sendTick=0;
	extern int32_t globalPeriodSendLoop;
  /* Infinite loop */
  for(;;)
  {
	  if(++sendTick>=globalPeriodSendLoop)
	  {
		  sendTick=0;
		  serialDisplay();
	  }
	  vTaskDelayUntil(&xLastWakeTime,sendTaskPeriod);
  }
  /* USER CODE END sendTaskFunc */
}

void controlTaskFunc(void const * argument)
{
  /* USER CODE BEGIN controlTaskFunc */
	TickType_t xLastWakeTime=xTaskGetTickCount();
	TickType_t controlTaskPeriod=pdMS_TO_TICKS(1);
	static int32_t loopTick=0;
	extern int32_t globalPeriodControlLoop;
  /* Infinite loop */
	 for(;;)
	  {

		//	AnaBuiltInStart();
	#if (ADBOARD_NUM>0)
			ADBoard_updateVoltage();
	#endif
			//terminal command process
			Usart_ReceivePolling();

			//User loop function
	 if(++loopTick>=globalPeriodControlLoop)
	 {
		loopTick=0;
		loop();
	 }

	#if (PWMBOARDSPI_NUM>0)
			PWMBoardSPI_flushDutyAll();
	#endif
			vTaskDelayUntil(&xLastWakeTime,controlTaskPeriod);

	  }
  /* USER CODE END controlTaskFunc */
}

/************************ (C) COPYRIGHT STMicroelectronics *****END OF FILE****/
